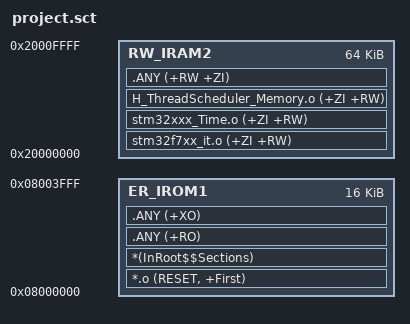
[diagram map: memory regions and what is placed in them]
; *************************************************************
; *** Scatter-Loading Description File generated by uVision ***
; *************************************************************

LR_IROM1 0x08000000 0x00004000  {    ; load region size_region
  ER_IROM1 0x08000000 0x00004000  {  ; load address = execution address
   *.o (RESET, +First)
   *(InRoot$$Sections)
   .ANY (+RO)
   .ANY (+XO)
  }
  RW_IRAM2 0x20000000 0x00010000  {  ; RW data
    stm32f7xx_it.o (+ZI +RW)
    stm32xxx_Time.o (+ZI +RW)
    H_ThreadScheduler_Memory.o (+ZI +RW)
   .ANY (+RW +ZI)
  }
}

